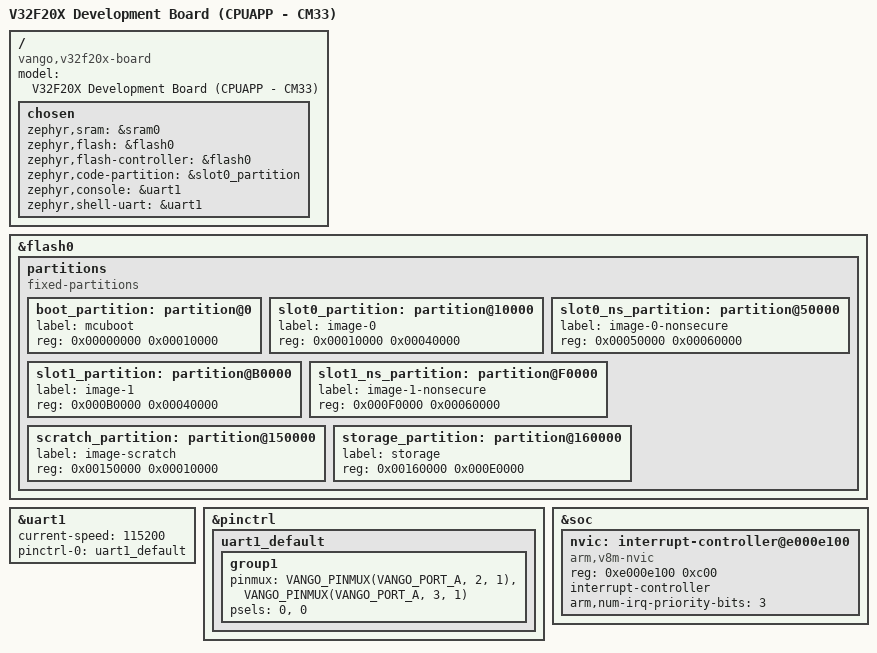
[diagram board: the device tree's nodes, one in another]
/dts-v1/;
#include <arm/vango/v32f20x/v32f20x.dtsi>

/ {
    model = "V32F20X Development Board (CPUAPP - CM33)";
    compatible = "vango,v32f20x-board";

    chosen {
        zephyr,sram = &sram0;
        zephyr,flash = &flash0;
        zephyr,flash-controller = &flash0;
        zephyr,code-partition = &slot0_partition;
        zephyr,console = &uart1;
        zephyr,shell-uart = &uart1;
    };
};

&flash0 {
    partitions {
        compatible = "fixed-partitions";
        #address-cells = <1>;
        #size-cells = <1>;

        boot_partition: partition@0 {
            label = "mcuboot";
            reg = <0x00000000 0x00010000>;
        };
        slot0_partition: partition@10000 {
            label = "image-0";
            reg = <0x00010000 0x00040000>;
        };
        slot0_ns_partition: partition@50000 {
            label = "image-0-nonsecure";
            reg = <0x00050000 0x00060000>;
        };
        slot1_partition: partition@B0000 {
            label = "image-1";
            reg = <0x000B0000 0x00040000>;
        };
        slot1_ns_partition: partition@F0000 {
            label = "image-1-nonsecure";
            reg = <0x000F0000 0x00060000>;
        };
        scratch_partition: partition@150000 {
            label = "image-scratch";
            reg = <0x00150000 0x00010000>;
        };
        storage_partition: partition@160000 {
            label = "storage";
            reg = <0x00160000 0x000E0000>;
        };
    };
};

&uart1 {
    status = "okay";
    current-speed = <115200>;
    pinctrl-0 = <&uart1_default>;
    pinctrl-names = "default";
};

&pinctrl {
    uart1_default: uart1_default {
        group1 {
            pinmux = <VANGO_PINMUX(VANGO_PORT_A, 2, 1)>,
                     <VANGO_PINMUX(VANGO_PORT_A, 3, 1)>;
            psels = <0>, <0>;
        };
    };
};

&soc {
    nvic: interrupt-controller@e000e100 {
        compatible = "arm,v8m-nvic";
        reg = <0xe000e100 0xc00>;
        interrupt-controller;
        #interrupt-cells = <2>;
        arm,num-irq-priority-bits = <3>;
    };
};
